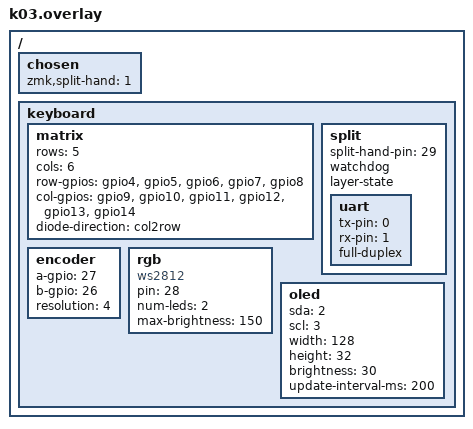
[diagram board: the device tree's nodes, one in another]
/dts-v1/;

/ {
    chosen {
        zmk,split-hand = <1>; /* 0 - правая, 1 - левая */
    };

    keyboard {
        matrix {
            rows = <5>;
            cols = <6>;
            row-gpios = <&gpio4 &gpio5 &gpio6 &gpio7 &gpio8>;
            col-gpios = <&gpio9 &gpio10 &gpio11 &gpio12 &gpio13 &gpio14>;
            diode-direction = "col2row";
        };

        split {
            split-hand-pin = <29>; /* GP29 */
            uart {
                tx-pin = <0>; /* GP0 */
                rx-pin = <1>; /* GP1 */
                full-duplex;
            };
            watchdog;
            layer-state;
        };

        encoder {
            a-gpio = <27>; /* GP27 */
            b-gpio = <26>; /* GP26 */
            resolution = <4>;
        };

        rgb {
            compatible = "ws2812";
            pin = <28>; /* GP28 */
            num-leds = <2>;
            max-brightness = <150>;
        };

        oled {
            sda = <2>; /* GP2 */
            scl = <3>; /* GP3 */
            width = <128>;
            height = <32>;
            brightness = <30>;
            update-interval-ms = <200>;
        };
    };
};

